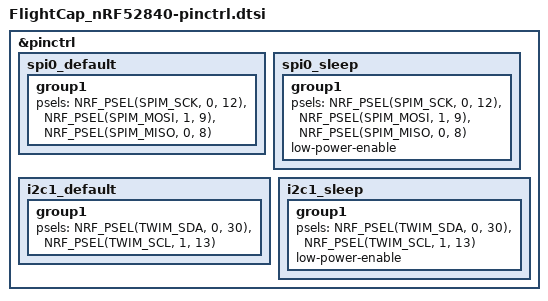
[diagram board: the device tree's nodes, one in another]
&pinctrl {
	spi0_default: spi0_default {
		group1 {
			psels = <NRF_PSEL(SPIM_SCK, 0, 12)>,
				<NRF_PSEL(SPIM_MOSI, 1, 9)>,
				<NRF_PSEL(SPIM_MISO, 0, 8)>;
		};
	};

	spi0_sleep: spi0_sleep {
		group1 {
			psels = <NRF_PSEL(SPIM_SCK, 0, 12)>,
				<NRF_PSEL(SPIM_MOSI, 1, 9)>,
				<NRF_PSEL(SPIM_MISO, 0, 8)>;
			low-power-enable;
		};
	};

	/*
	 * I2C1 (TWIM1) pinout — SDA on P0.30 is a Low-Frequency I/O pin per
	 * the nRF52840 product spec. Standard-mode (100 kHz) keeps the bus
	 * within the LF-I/O slew envelope; see notes in the .dts.
	 */
	i2c1_default: i2c1_default {
		group1 {
			psels = <NRF_PSEL(TWIM_SDA, 0, 30)>,
				<NRF_PSEL(TWIM_SCL, 1, 13)>;
		};
	};

	i2c1_sleep: i2c1_sleep {
		group1 {
			psels = <NRF_PSEL(TWIM_SDA, 0, 30)>,
				<NRF_PSEL(TWIM_SCL, 1, 13)>;
			low-power-enable;
		};
	};
};
